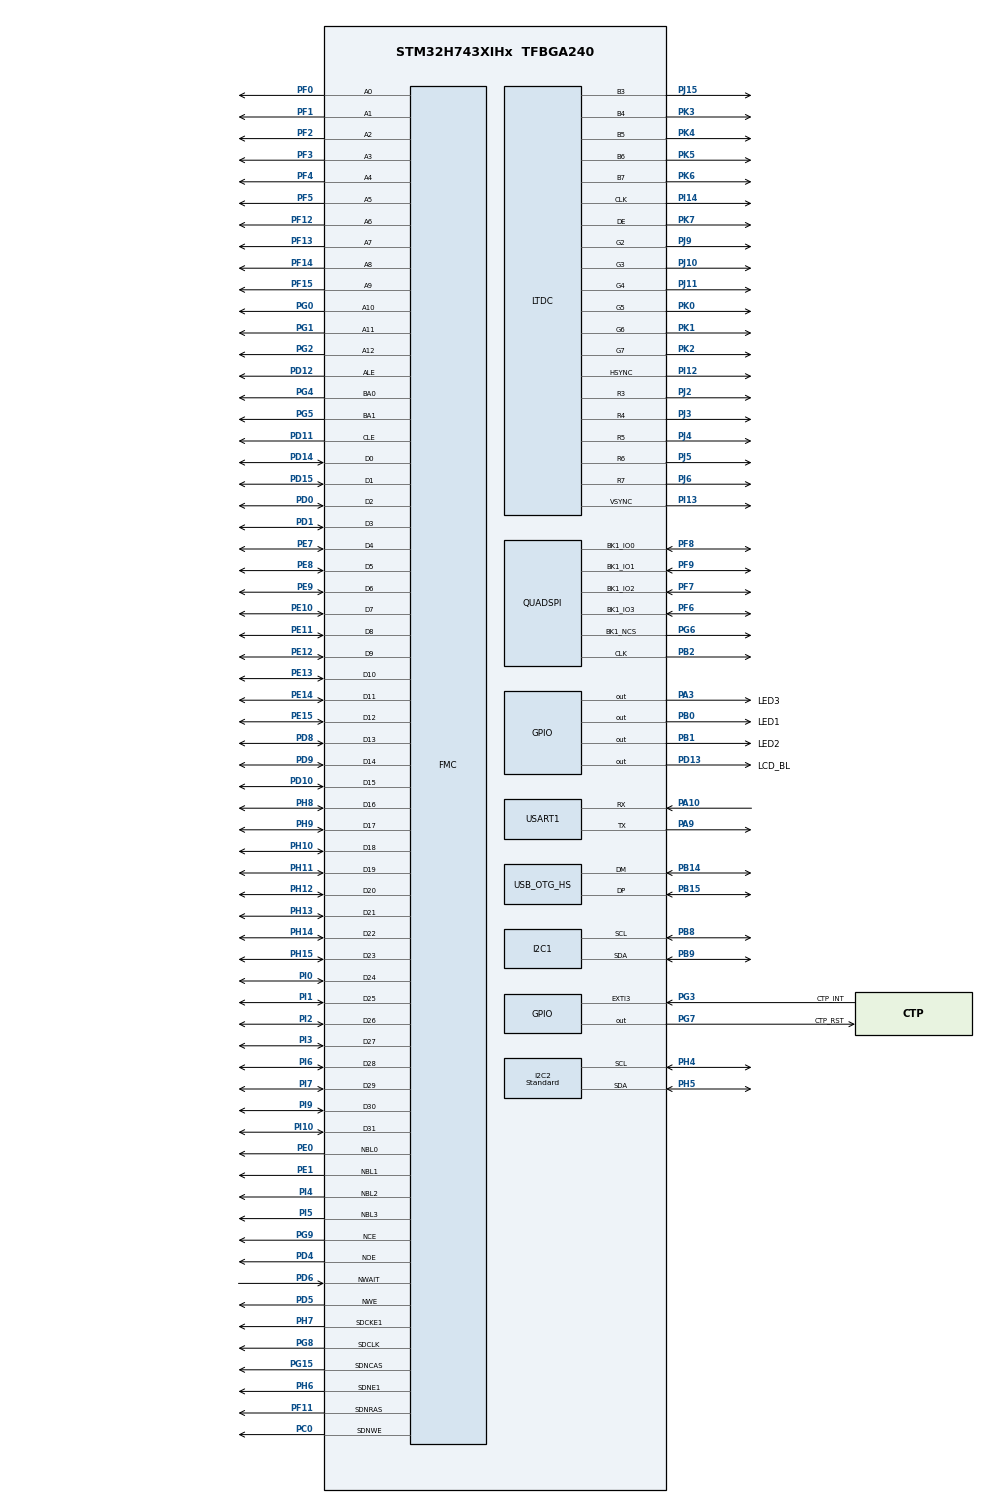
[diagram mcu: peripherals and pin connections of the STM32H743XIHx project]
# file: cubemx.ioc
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CORTEX_M7.default_mode_Activation=1
DMA2D.ColorMode=DMA2D_OUTPUT_RGB565
FATFS._USE_LABEL=1
FATFS._USE_LFN=3
FMC.CASLatency2=FMC_SDRAM_CAS_LATENCY_3
FMC.ColumnBitsNumber2=FMC_SDRAM_COLUMN_BITS_NUM_9
FMC.ExitSelfRefreshDelay2=8
FMC.LoadToActiveDelay2=2
FMC.RCDDelay2=2
FMC.RPDelay2=2
FMC.ReadBurst2=FMC_SDRAM_RBURST_ENABLE
FMC.ReadPipeDelay2=FMC_SDRAM_RPIPE_DELAY_1
FMC.RowCycleDelay2=8
FMC.SDClockPeriod2=FMC_SDRAM_CLOCK_PERIOD_2
FMC.SelfRefreshTime2=5
FMC.WriteRecoveryTime2=4
FREERTOS.Tasks01=defaultTask,24,128,StartDefaultTask,Default,NULL,Dynamic,NULL,NULL
FREERTOS.configENABLE_FPU=1
FREERTOS.configTOTAL_HEAP_SIZE=30720
I2C1.Timing=0x307075B1
I2C2.I2C_Speed_Mode=I2C_Standard
I2C2.Speed=100
I2C2.Timing=0x307075B1
LTDC.ActiveW=800
LTDC.Alpha_L0=255
LTDC.FBStartAdress_L0=0xD0000000
LTDC.HBP=46
LTDC.HFP=40
LTDC.HSync=1
LTDC.ImageHeight_L0=480
LTDC.ImageWidth_L0=800
LTDC.ImageWidth_L1=0
LTDC.PixelFormat_L0=LTDC_PIXEL_FORMAT_RGB565
LTDC.PixelFormat_L1=LTDC_PIXEL_FORMAT_ARGB8888
LTDC.VBP=23
LTDC.VFP=13
LTDC.VSync=3
LTDC.WindowX1_L0=800
LTDC.WindowY1_L0=480
Mcu.Family=STM32H7
Mcu.Name=STM32H743XIHx
Mcu.Package=TFBGA240
NVIC.DMA2D_IRQn=true\:5\:0\:false\:false\:true\:true\:true\:true\:true
NVIC.EXTI3_IRQn=true\:5\:0\:false\:false\:true\:true\:true\:true\:true
NVIC.OTG_HS_IRQn=true\:5\:0\:false\:false\:true\:true\:false\:true\:true
NVIC.PriorityGroup=NVIC_PRIORITYGROUP_4
NVIC.TIM6_DAC_IRQn=true\:15\:0\:false\:false\:true\:false\:false\:true\:true
NVIC.TimeBase=TIM6_DAC_IRQn
NVIC.TimeBaseIP=TIM6
PA10.Mode=Asynchronous
PA10.Signal=USART1_RX
PA13\ (JTMS/SWDIO).Mode=Serial_Wire
PA13\ (JTMS/SWDIO).Signal=DEBUG_JTMS-SWDIO
PA14\ (JTCK/SWCLK).Mode=Serial_Wire
PA14\ (JTCK/SWCLK).Signal=DEBUG_JTCK-SWCLK
PA3.GPIO_Label=LED3
PA3.GPIO_Speed=GPIO_SPEED_FREQ_HIGH
PA3.PinState=GPIO_PIN_SET
PA3.Signal=GPIO_Output
PA9.Mode=Asynchronous
PA9.Signal=USART1_TX
PB0.GPIO_Label=LED1
PB0.GPIO_Speed=GPIO_SPEED_FREQ_HIGH
PB0.PinState=GPIO_PIN_SET
PB0.Signal=GPIO_Output
PB1.GPIO_Label=LED2
PB1.GPIO_Speed=GPIO_SPEED_FREQ_HIGH
PB1.PinState=GPIO_PIN_SET
PB1.Signal=GPIO_Output
PB14.GPIO_Speed=GPIO_SPEED_FREQ_MEDIUM
PB14.Mode=Device_Only_FS
PB14.Signal=USB_OTG_HS_DM
PB15.GPIO_Speed=GPIO_SPEED_FREQ_MEDIUM
PB15.Mode=Device_Only_FS
PB15.Signal=USB_OTG_HS_DP
PB2.GPIO_Speed=GPIO_SPEED_FREQ_VERY_HIGH
PB2.Mode=Single Bank 1
PB2.Signal=QUADSPI_CLK
PB8.Mode=I2C
PB8.Signal=I2C1_SCL
PB9.Mode=I2C
PB9.Signal=I2C1_SDA
PC0.Signal=FMC_SDNWE
PC14-OSC32_IN\ (OSC32_IN).Mode=LSE-External-Oscillator
PC14-OSC32_IN\ (OSC32_IN).Signal=RCC_OSC32_IN
PC15-OSC32_OUT\ (OSC32_OUT).Mode=LSE-External-Oscillator
PC15-OSC32_OUT\ (OSC32_OUT).Signal=RCC_OSC32_OUT
PD0.Signal=FMC_D2_DA2
PD1.Signal=FMC_D3_DA3
PD10.Signal=FMC_D15_DA15
PD11.Signal=FMC_A16_CLE
PD12.Signal=FMC_A17_ALE
PD13.GPIO_Label=LCD_BL
PD13.GPIO_Speed=GPIO_SPEED_FREQ_HIGH
PD13.PinState=GPIO_PIN_RESET
PD13.Signal=GPIO_Output
PD14.Signal=FMC_D0_DA0
PD15.Signal=FMC_D1_DA1
PD4.Signal=FMC_NOE
PD5.Signal=FMC_NWE
PD6.Signal=FMC_NWAIT
PD8.Signal=FMC_D13_DA13
PD9.Signal=FMC_D14_DA14
PE0.Signal=FMC_NBL0
PE1.Signal=FMC_NBL1
PE10.Signal=FMC_D7_DA7
PE11.Signal=FMC_D8_DA8
PE12.Signal=FMC_D9_DA9
PE13.Signal=FMC_D10_DA10
PE14.Signal=FMC_D11_DA11
PE15.Signal=FMC_D12_DA12
PE7.Signal=FMC_D4_DA4
PE8.Signal=FMC_D5_DA5
PE9.Signal=FMC_D6_DA6
PF0.Signal=FMC_A0
PF1.Signal=FMC_A1
PF11.Signal=FMC_SDNRAS
PF12.Signal=FMC_A6
PF13.Signal=FMC_A7
PF14.Signal=FMC_A8
PF15.Signal=FMC_A9
PF2.Signal=FMC_A2
PF3.Signal=FMC_A3
PF4.Signal=FMC_A4
PF5.Signal=FMC_A5
PF6.GPIO_Speed=GPIO_SPEED_FREQ_VERY_HIGH
PF6.Mode=Single Bank 1
PF6.Signal=QUADSPI_BK1_IO3
PF7.GPIO_Speed=GPIO_SPEED_FREQ_VERY_HIGH
PF7.Mode=Single Bank 1
PF7.Signal=QUADSPI_BK1_IO2
PF8.GPIO_Speed=GPIO_SPEED_FREQ_VERY_HIGH
PF8.Mode=Single Bank 1
PF8.Signal=QUADSPI_BK1_IO0
PF9.GPIO_Speed=GPIO_SPEED_FREQ_VERY_HIGH
PF9.Mode=Single Bank 1
PF9.Signal=QUADSPI_BK1_IO1
PG0.Signal=FMC_A10
PG1.Signal=FMC_A11
PG15.Signal=FMC_SDNCAS
PG2.Signal=FMC_A12
PG3.GPIO_Label=CTP_INT
PG3.Signal=GPXTI3
PG4.Signal=FMC_A14_BA0
PG5.Signal=FMC_A15_BA1
PG6.GPIO_Speed=GPIO_SPEED_FREQ_VERY_HIGH
PG6.Mode=Single Bank 1
PG6.Signal=QUADSPI_BK1_NCS
PG7.GPIO_Label=CTP_RST
PG7.GPIO_Speed=GPIO_SPEED_FREQ_HIGH
PG7.Signal=GPIO_Output
PG8.Signal=FMC_SDCLK
PG9.Mode=NandChipSelect3_1
PG9.Signal=FMC_NCE
PH0-OSC_IN\ (PH0).Mode=HSE-External-Oscillator
PH0-OSC_IN\ (PH0).Signal=RCC_OSC_IN
PH1-OSC_OUT\ (PH1).Mode=HSE-External-Oscillator
PH1-OSC_OUT\ (PH1).Signal=RCC_OSC_OUT
PH10.Signal=FMC_D18
PH11.Signal=FMC_D19
PH12.Signal=FMC_D20
PH13.Signal=FMC_D21
PH14.Signal=FMC_D22
PH15.Signal=FMC_D23
PH4.GPIO_Speed=GPIO_SPEED_FREQ_VERY_HIGH
PH4.Mode=I2C
PH4.Signal=I2C2_SCL
PH5.GPIO_Speed=GPIO_SPEED_FREQ_VERY_HIGH
PH5.Mode=I2C
PH5.Signal=I2C2_SDA
PH6.Mode=SdramChipSelect2_2
PH6.Signal=FMC_SDNE1
PH7.Mode=SdramChipSelect2_2
PH7.Signal=FMC_SDCKE1
PH8.Signal=FMC_D16
PH9.Signal=FMC_D17
PI0.Signal=FMC_D24
PI1.Signal=FMC_D25
PI10.Signal=FMC_D31
PI12.GPIO_Speed=GPIO_SPEED_FREQ_HIGH
PI12.Mode=RGB565
PI12.Signal=LTDC_HSYNC
PI13.GPIO_Speed=GPIO_SPEED_FREQ_HIGH
PI13.Mode=RGB565
PI13.Signal=LTDC_VSYNC
PI14.GPIO_Speed=GPIO_SPEED_FREQ_HIGH
PI14.Mode=RGB565
PI14.Signal=LTDC_CLK
PI2.Signal=FMC_D26
PI3.Signal=FMC_D27
PI4.Signal=FMC_NBL2
PI5.Signal=FMC_NBL3
PI6.Signal=FMC_D28
PI7.Signal=FMC_D29
PI9.Signal=FMC_D30
PJ10.GPIO_Speed=GPIO_SPEED_FREQ_HIGH
PJ10.Mode=RGB565
PJ10.Signal=LTDC_G3
PJ11.GPIO_Speed=GPIO_SPEED_FREQ_HIGH
PJ11.Mode=RGB565
PJ11.Signal=LTDC_G4
PJ15.GPIO_Speed=GPIO_SPEED_FREQ_HIGH
PJ15.Mode=RGB565
PJ15.Signal=LTDC_B3
PJ2.GPIO_Speed=GPIO_SPEED_FREQ_HIGH
PJ2.Mode=RGB565
PJ2.Signal=LTDC_R3
PJ3.GPIO_Speed=GPIO_SPEED_FREQ_HIGH
PJ3.Mode=RGB565
PJ3.Signal=LTDC_R4
PJ4.GPIO_Speed=GPIO_SPEED_FREQ_HIGH
PJ4.Mode=RGB565
PJ4.Signal=LTDC_R5
PJ5.GPIO_Speed=GPIO_SPEED_FREQ_HIGH
PJ5.Mode=RGB565
PJ5.Signal=LTDC_R6
PJ6.GPIO_Speed=GPIO_SPEED_FREQ_HIGH
PJ6.Mode=RGB565
PJ6.Signal=LTDC_R7
PJ9.GPIO_Speed=GPIO_SPEED_FREQ_HIGH
PJ9.Mode=RGB565
PJ9.Signal=LTDC_G2
PK0.GPIO_Speed=GPIO_SPEED_FREQ_HIGH
PK0.Mode=RGB565
PK0.Signal=LTDC_G5
PK1.GPIO_Speed=GPIO_SPEED_FREQ_HIGH
PK1.Mode=RGB565
PK1.Signal=LTDC_G6
PK2.GPIO_Speed=GPIO_SPEED_FREQ_HIGH
PK2.Mode=RGB565
PK2.Signal=LTDC_G7
PK3.GPIO_Speed=GPIO_SPEED_FREQ_HIGH
PK3.Mode=RGB565
PK3.Signal=LTDC_B4
PK4.GPIO_Speed=GPIO_SPEED_FREQ_HIGH
PK4.Mode=RGB565
PK4.Signal=LTDC_B5
PK5.GPIO_Speed=GPIO_SPEED_FREQ_HIGH
PK5.Mode=RGB565
PK5.Signal=LTDC_B6
PK6.GPIO_Speed=GPIO_SPEED_FREQ_HIGH
PK6.Mode=RGB565
PK6.Signal=LTDC_B7
PK7.GPIO_Speed=GPIO_SPEED_FREQ_HIGH
PK7.Mode=RGB565
PK7.Signal=LTDC_DE
ProjectManager.HeapSize=0x200
ProjectManager.StackSize=0x1000
ProjectManager.TargetToolchain=MDK-ARM V5.32
QUADSPI.ChipSelectHighTime=QSPI_CS_HIGH_TIME_6_CYCLE
QUADSPI.ClockMode=QSPI_CLOCK_MODE_0
QUADSPI.ClockPrescaler=3
QUADSPI.FifoThreshold=4
QUADSPI.FlashSize=24
QUADSPI.SampleShifting=QSPI_SAMPLE_SHIFTING_HALFCYCLE
RCC.ADCFreq_Value=50390625
RCC.APB1Freq_Value=120000000
RCC.APB2Freq_Value=120000000
RCC.APB3Freq_Value=120000000
RCC.APB4Freq_Value=120000000
RCC.CortexFreq_Value=480000000
RCC.D1PPRE=RCC_APB3_DIV2
RCC.D2PPRE1=RCC_APB1_DIV2
RCC.D2PPRE2=RCC_APB2_DIV2
RCC.D3PPRE=RCC_APB4_DIV2
RCC.DIVM1=5
RCC.DIVM3=5
RCC.DIVN1=192
RCC.DIVN3=105
RCC.DIVQ3=11
RCC.DIVR3=16
RCC.HCLKFreq_Value=240000000
RCC.HPRE=RCC_HCLK_DIV2
RCC.PLL2FRACN=0
RCC.PLL3FRACN=4915
RCC.PLLFRACN=0
RCC.PLLSourceVirtual=RCC_PLLSOURCE_HSE
RCC.RTCClockSelection=RCC_RTCCLKSOURCE_LSE
RCC.SYSCLKFreq_VALUE=480000000
RCC.SYSCLKSource=RCC_SYSCLKSOURCE_PLLCLK
RCC.USBCLockSelection=RCC_USBCLKSOURCE_PLL3
RCC.USBFreq_Value=47999988.90269887
SH.FMC_A0.0=FMC_A0,13b-sda2
SH.FMC_A1.0=FMC_A1,13b-sda2
SH.FMC_A10.0=FMC_A10,13b-sda2
SH.FMC_A11.0=FMC_A11,13b-sda2
SH.FMC_A12.0=FMC_A12,13b-sda2
SH.FMC_A14_BA0.0=FMC_BA0,FourSdramBanks2
SH.FMC_A15_BA1.0=FMC_BA1,FourSdramBanks2
SH.FMC_A16_CLE.0=FMC_CLE,8b-dmux1
SH.FMC_A17_ALE.0=FMC_ALE,8b-dmux1
SH.FMC_A2.0=FMC_A2,13b-sda2
SH.FMC_A3.0=FMC_A3,13b-sda2
SH.FMC_A4.0=FMC_A4,13b-sda2
SH.FMC_A5.0=FMC_A5,13b-sda2
SH.FMC_A6.0=FMC_A6,13b-sda2
SH.FMC_A7.0=FMC_A7,13b-sda2
SH.FMC_A8.0=FMC_A8,13b-sda2
SH.FMC_A9.0=FMC_A9,13b-sda2
SH.FMC_D0_DA0.0=FMC_D0,sd-32b-d2
SH.FMC_D0_DA0.1=FMC_D0,8b-dmux1
SH.FMC_D10_DA10.0=FMC_D10,sd-32b-d2
SH.FMC_D11_DA11.0=FMC_D11,sd-32b-d2
SH.FMC_D12_DA12.0=FMC_D12,sd-32b-d2
SH.FMC_D13_DA13.0=FMC_D13,sd-32b-d2
SH.FMC_D14_DA14.0=FMC_D14,sd-32b-d2
SH.FMC_D15_DA15.0=FMC_D15,sd-32b-d2
SH.FMC_D16.0=FMC_D16,sd-32b-d2
SH.FMC_D17.0=FMC_D17,sd-32b-d2
SH.FMC_D18.0=FMC_D18,sd-32b-d2
SH.FMC_D19.0=FMC_D19,sd-32b-d2
SH.FMC_D1_DA1.0=FMC_D1,sd-32b-d2
SH.FMC_D1_DA1.1=FMC_D1,8b-dmux1
SH.FMC_D20.0=FMC_D20,sd-32b-d2
SH.FMC_D21.0=FMC_D21,sd-32b-d2
SH.FMC_D22.0=FMC_D22,sd-32b-d2
SH.FMC_D23.0=FMC_D23,sd-32b-d2
SH.FMC_D24.0=FMC_D24,sd-32b-d2
SH.FMC_D25.0=FMC_D25,sd-32b-d2
SH.FMC_D26.0=FMC_D26,sd-32b-d2
SH.FMC_D27.0=FMC_D27,sd-32b-d2
SH.FMC_D28.0=FMC_D28,sd-32b-d2
SH.FMC_D29.0=FMC_D29,sd-32b-d2
SH.FMC_D2_DA2.0=FMC_D2,sd-32b-d2
SH.FMC_D2_DA2.1=FMC_D2,8b-dmux1
SH.FMC_D30.0=FMC_D30,sd-32b-d2
SH.FMC_D31.0=FMC_D31,sd-32b-d2
SH.FMC_D3_DA3.0=FMC_D3,sd-32b-d2
SH.FMC_D3_DA3.1=FMC_D3,8b-dmux1
SH.FMC_D4_DA4.0=FMC_D4,sd-32b-d2
SH.FMC_D4_DA4.1=FMC_D4,8b-dmux1
SH.FMC_D5_DA5.0=FMC_D5,sd-32b-d2
SH.FMC_D5_DA5.1=FMC_D5,8b-dmux1
SH.FMC_D6_DA6.0=FMC_D6,sd-32b-d2
SH.FMC_D6_DA6.1=FMC_D6,8b-dmux1
SH.FMC_D7_DA7.0=FMC_D7,sd-32b-d2
SH.FMC_D7_DA7.1=FMC_D7,8b-dmux1
SH.FMC_D8_DA8.0=FMC_D8,sd-32b-d2
SH.FMC_D9_DA9.0=FMC_D9,sd-32b-d2
SH.FMC_NBL0.0=FMC_NBL0,Sd4ByteEnable2
SH.FMC_NBL1.0=FMC_NBL1,Sd4ByteEnable2
SH.FMC_NBL2.0=FMC_NBL2,Sd4ByteEnable2
SH.FMC_NBL3.0=FMC_NBL3,Sd4ByteEnable2
SH.FMC_NOE.0=FMC_NOE,8b-dmux1
SH.FMC_NWAIT.0=FMC_NWAIT,Wait1
SH.FMC_NWE.0=FMC_NWE,8b-dmux1
SH.FMC_SDCLK.0=FMC_SDCLK,13b-sda2
SH.FMC_SDNCAS.0=FMC_SDNCAS,13b-sda2
SH.FMC_SDNRAS.0=FMC_SDNRAS,13b-sda2
SH.FMC_SDNWE.0=FMC_SDNWE,13b-sda2
USART1.VirtualMode-Asynchronous=VM_ASYNC
USB_DEVICE.CLASS_NAME_HS=MSC
USB_DEVICE.MANUFACTURER_STRING-MSC_HS=ZLB
USB_DEVICE.PRODUCT_STRING_MSC_HS=STM32 QSPI Flash Disk
USB_DEVICE.VirtualMode-MSC_HS=Msc
USB_DEVICE.VirtualModeHS=Msc_HS
USB_OTG_HS.VirtualMode-Device_Only_FS=Device_Only_FS
VP_DMA2D_VS_DMA2D.Mode=DMA2D_Activate
VP_FATFS_VS_Generic.Mode=User_defined
VP_FREERTOS_VS_CMSIS_V2.Mode=CMSIS_V2
VP_MEMORYMAP_VS_MEMORYMAP.Mode=CurAppReg
VP_RTC_VS_RTC_Activate.Mode=RTC_Enabled
VP_SYS_VS_tim6.Mode=TIM6
VP_USB_DEVICE_VS_USB_DEVICE_MSC_HS.Mode=MSC_HS
board=custom

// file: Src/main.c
/* USER CODE BEGIN Header */
/**
  ******************************************************************************
  * @file           : main.c
  * @brief          : Main program body
  ******************************************************************************
  * @attention
  *
  * Copyright (c) 2026 STMicroelectronics.
  * All rights reserved.
  *
  * This software is licensed under terms that can be found in the LICENSE file
  * in the root directory of this software component.
  * If no LICENSE file comes with this software, it is provided AS-IS.
  *
  ******************************************************************************
  */
/* USER CODE END Header */
#include "main.h"
#include "FreeRTOS.h"
#include "cmsis_os2.h"
#include "dma2d.h"
#include "fatfs.h"
#include "i2c.h"
#include "ltdc.h"
#include "quadspi.h"
#include "rtc.h"
#include "usart.h"
#include "usb_device.h"
#include "gpio.h"
#include "fmc.h"

/* USER CODE BEGIN Includes */
#include "w25q256.h"
#include "stdio.h"
#include "string.h"
/* USER CODE END Includes */

void SystemClock_Config(void);
void PeriphCommonClock_Config(void);
static void MPU_Config(void);
void MX_FREERTOS_Init(void);

int main(void)
{

  /* MPU Configuration--------------------------------------------------------*/
  MPU_Config();

  /* MCU Configuration--------------------------------------------------------*/

  /* Reset of all peripherals, Initializes the Flash interface and the Systick. */
  HAL_Init();

  /* Configure the system clock */
  SystemClock_Config();

  /* Configure the peripherals common clocks */
  PeriphCommonClock_Config();

  /* Initialize all configured peripherals */
  MX_USART1_UART_Init();
  MX_GPIO_Init();
  MX_LTDC_Init();
  MX_RTC_Init();
  MX_DMA2D_Init();
  MX_I2C2_Init();
  MX_FMC_Init();
  MX_QUADSPI_Init();
  MX_I2C1_Init();
  //MX_FATFS_Init();

  /* Init scheduler */
  osKernelInitialize();  /* Call init function for freertos objects (in cmsis_os2.c) */
  MX_FREERTOS_Init();

  /* Start scheduler */
  osKernelStart();

  /* We should never get here as control is now taken by the scheduler */

  /* Infinite loop */
  while (1)
  {

  }
}

void SystemClock_Config(void)
{
  RCC_OscInitTypeDef RCC_OscInitStruct = {0};
  RCC_ClkInitTypeDef RCC_ClkInitStruct = {0};

  /** Supply configuration update enable
  */
  HAL_PWREx_ConfigSupply(PWR_LDO_SUPPLY);

  /** Configure the main internal regulator output voltage
  */
  __HAL_PWR_VOLTAGESCALING_CONFIG(PWR_REGULATOR_VOLTAGE_SCALE0);

  while(!__HAL_PWR_GET_FLAG(PWR_FLAG_VOSRDY)) {}

  /** Configure LSE Drive Capability
  */
  HAL_PWR_EnableBkUpAccess();
  __HAL_RCC_LSEDRIVE_CONFIG(RCC_LSEDRIVE_LOW);

  /** Initializes the RCC Oscillators according to the specified parameters
  * in the RCC_OscInitTypeDef structure.
  */
  RCC_OscInitStruct.OscillatorType = RCC_OSCILLATORTYPE_HSE|RCC_OSCILLATORTYPE_LSE;
  RCC_OscInitStruct.HSEState = RCC_HSE_ON;
  RCC_OscInitStruct.LSEState = RCC_LSE_ON;
  RCC_OscInitStruct.PLL.PLLState = RCC_PLL_ON;
  RCC_OscInitStruct.PLL.PLLSource = RCC_PLLSOURCE_HSE;
  RCC_OscInitStruct.PLL.PLLM = 5;
  RCC_OscInitStruct.PLL.PLLN = 192;
  RCC_OscInitStruct.PLL.PLLP = 2;
  RCC_OscInitStruct.PLL.PLLQ = 2;
  RCC_OscInitStruct.PLL.PLLR = 2;
  RCC_OscInitStruct.PLL.PLLRGE = RCC_PLL1VCIRANGE_2;
  RCC_OscInitStruct.PLL.PLLVCOSEL = RCC_PLL1VCOWIDE;
  RCC_OscInitStruct.PLL.PLLFRACN = 0;
  if (HAL_RCC_OscConfig(&RCC_OscInitStruct) != HAL_OK)
  {
    Error_Handler();
  }

  /** Initializes the CPU, AHB and APB buses clocks
  */
  RCC_ClkInitStruct.ClockType = RCC_CLOCKTYPE_HCLK|RCC_CLOCKTYPE_SYSCLK
                              |RCC_CLOCKTYPE_PCLK1|RCC_CLOCKTYPE_PCLK2
                              |RCC_CLOCKTYPE_D3PCLK1|RCC_CLOCKTYPE_D1PCLK1;
  RCC_ClkInitStruct.SYSCLKSource = RCC_SYSCLKSOURCE_PLLCLK;
  RCC_ClkInitStruct.SYSCLKDivider = RCC_SYSCLK_DIV1;
  RCC_ClkInitStruct.AHBCLKDivider = RCC_HCLK_DIV2;
  RCC_ClkInitStruct.APB3CLKDivider = RCC_APB3_DIV2;
  RCC_ClkInitStruct.APB1CLKDivider = RCC_APB1_DIV2;
  RCC_ClkInitStruct.APB2CLKDivider = RCC_APB2_DIV2;
  RCC_ClkInitStruct.APB4CLKDivider = RCC_APB4_DIV2;

  if (HAL_RCC_ClockConfig(&RCC_ClkInitStruct, FLASH_LATENCY_4) != HAL_OK)
  {
    Error_Handler();
  }
}

void PeriphCommonClock_Config(void)
{
  RCC_PeriphCLKInitTypeDef PeriphClkInitStruct = {0};

  /** Initializes the peripherals clock
  */
  PeriphClkInitStruct.PeriphClockSelection = RCC_PERIPHCLK_USB|RCC_PERIPHCLK_LTDC;
  PeriphClkInitStruct.PLL3.PLL3M = 5;
  PeriphClkInitStruct.PLL3.PLL3N = 105;
  PeriphClkInitStruct.PLL3.PLL3P = 2;
  PeriphClkInitStruct.PLL3.PLL3Q = 11;
  PeriphClkInitStruct.PLL3.PLL3R = 16;
  PeriphClkInitStruct.PLL3.PLL3RGE = RCC_PLL3VCIRANGE_2;
  PeriphClkInitStruct.PLL3.PLL3VCOSEL = RCC_PLL3VCOWIDE;
  PeriphClkInitStruct.PLL3.PLL3FRACN = 4915;
  PeriphClkInitStruct.UsbClockSelection = RCC_USBCLKSOURCE_PLL3;
  if (HAL_RCCEx_PeriphCLKConfig(&PeriphClkInitStruct) != HAL_OK)
  {
    Error_Handler();
  }
}

 /* MPU Configuration */

void MPU_Config(void)
{
  MPU_Region_InitTypeDef MPU_InitStruct = {0};

  /* Disables the MPU */
  HAL_MPU_Disable();

  /** Initializes and configures the Region and the memory to be protected
  */
  MPU_InitStruct.Enable = MPU_REGION_ENABLE;
  MPU_InitStruct.Number = MPU_REGION_NUMBER0;
  MPU_InitStruct.BaseAddress = 0x0;
  MPU_InitStruct.Size = MPU_REGION_SIZE_4GB;
  MPU_InitStruct.SubRegionDisable = 0x87;
  MPU_InitStruct.TypeExtField = MPU_TEX_LEVEL1;
  MPU_InitStruct.AccessPermission = MPU_REGION_NO_ACCESS;
  MPU_InitStruct.DisableExec = MPU_INSTRUCTION_ACCESS_DISABLE;
  MPU_InitStruct.IsShareable = MPU_ACCESS_NOT_SHAREABLE;
  MPU_InitStruct.IsCacheable = MPU_ACCESS_NOT_CACHEABLE;
  MPU_InitStruct.IsBufferable = MPU_ACCESS_NOT_BUFFERABLE;

  HAL_MPU_ConfigRegion(&MPU_InitStruct);

  /** Initializes and configures the Region and the memory to be protected
  * 外部 SDRAM: 64MB，给 framebuffer 和 LVGL heap 使用。
  * 先按非缓存区域打开，优先确保 LTDC/LVGL 访问稳定，不引入 cache 一致性问题。
  */
  MPU_InitStruct.Number = MPU_REGION_NUMBER1;
  MPU_InitStruct.BaseAddress = 0xD0000000;
  MPU_InitStruct.Size = MPU_REGION_SIZE_64MB;
  MPU_InitStruct.SubRegionDisable = 0x00;
  MPU_InitStruct.TypeExtField = MPU_TEX_LEVEL1;
  MPU_InitStruct.AccessPermission = MPU_REGION_FULL_ACCESS;
  MPU_InitStruct.DisableExec = MPU_INSTRUCTION_ACCESS_DISABLE;
  MPU_InitStruct.IsShareable = MPU_ACCESS_NOT_SHAREABLE;
  MPU_InitStruct.IsCacheable = MPU_ACCESS_NOT_CACHEABLE;
  MPU_InitStruct.IsBufferable = MPU_ACCESS_NOT_BUFFERABLE;
  HAL_MPU_ConfigRegion(&MPU_InitStruct);

  /* Enables the MPU */
  HAL_MPU_Enable(MPU_PRIVILEGED_DEFAULT);

}

void HAL_TIM_PeriodElapsedCallback(TIM_HandleTypeDef *htim)
{
  if (htim->Instance == TIM6)
  {
    HAL_IncTick();
  }
}

void Error_Handler(void)
{
  __disable_irq();
  while (1)
  {
  }
}

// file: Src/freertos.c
/* USER CODE BEGIN Header */
/**
  ******************************************************************************
  * File Name          : freertos.c
  * Description        : Code for freertos applications
  ******************************************************************************
  * @attention
  *
  * Copyright (c) 2026 STMicroelectronics.
  * All rights reserved.
  *
  * This software is licensed under terms that can be found in the LICENSE file
  * in the root directory of this software component.
  * If no LICENSE file comes with this software, it is provided AS-IS.
  *
  ******************************************************************************
  */
/* USER CODE END Header */

#include "FreeRTOS.h"
#include "task.h"
#include "main.h"
#include "FreeRTOS.h"
#include "cmsis_os2.h"

/* USER CODE BEGIN Includes */
#include <string.h>
#include "initial.h"
#include "lvgl.h"
#include "gui_test_app.h"
#include "custom.h"
#include "events_init.h"
/* USER CODE END Includes */

/* USER CODE BEGIN Variables */
osSemaphoreId_t LvglReadySemHandle;

/* USER CODE END Variables */
/* Definitions for defaultTask */
osThreadId_t defaultTaskHandle;
const osThreadAttr_t defaultTask_attributes = {
  .name = "defaultTask",
  .stack_size = 128 * 4,
  .priority = (osPriority_t) osPriorityNormal,
};

/* USER CODE BEGIN FunctionPrototypes */
osThreadId_t Initial_TaskHandle;
const osThreadAttr_t Initial_Task_attributes = {
  .name = "Initial_Task",
  .stack_size = 1024 * 4,
  .priority = (osPriority_t) osPriorityNormal,
};
osThreadId_t Display_TaskHandle;
const osThreadAttr_t Display_Task_attributes = {
  .name = "Display_Task",
  .stack_size = 4096 * 4,
  .priority = (osPriority_t) osPriorityNormal,
};
/* USER CODE END FunctionPrototypes */

void StartDefaultTask(void *argument);
void MX_FREERTOS_Init(void); /* (MISRA C 2004 rule 8.1) */
void Initial_Task(void *argument);
void Display_Task(void *argument);

void MX_FREERTOS_Init(void) {

  /* USER CODE BEGIN RTOS_SEMAPHORES */
  /* add semaphores, ... */
  LvglReadySemHandle = osSemaphoreNew(1, 0, NULL);
  /* USER CODE END RTOS_SEMAPHORES */

  /* Create the thread(s) */
  /* creation of defaultTask */
  defaultTaskHandle = osThreadNew(StartDefaultTask, NULL, &defaultTask_attributes);

  /* USER CODE BEGIN RTOS_THREADS */
  /* add threads, ... */
  Initial_TaskHandle = osThreadNew(Initial_Task, NULL, &Initial_Task_attributes);
  Display_TaskHandle = osThreadNew(Display_Task, NULL, &Display_Task_attributes);
  /* USER CODE END RTOS_THREADS */

}

void StartDefaultTask(void *argument)
{
  /* USER CODE BEGIN StartDefaultTask */

  /* Infinite loop */
  for(;;)
  {
    HAL_GPIO_TogglePin(LED1_GPIO_Port, LED1_Pin);
    osDelay(1000);
  }
  /* USER CODE END StartDefaultTask */
}

/* USER CODE BEGIN Application */
void Initial_Task(void *argument)
{
  initial();
  // initial() 完成前，Display_Task 不能碰任何 LVGL API，否则会在 setup_ui 里踩到未完成初始化的内存系统。
  osSemaphoreRelease(LvglReadySemHandle);
  Initial_TaskHandle = NULL;//严谨一点，把句柄删除了，防止误用
  osThreadExit();
}
void Display_Task(void *argument)
{
  osSemaphoreAcquire(LvglReadySemHandle, osWaitForever);// 等待 LVGL 初始化完成的信号。
  LvglReadySemHandle = NULL; // 严谨一点，把句柄删除了，防止误用。
  osSemaphoreDelete(LvglReadySemHandle);// 同样严谨一点，删除信号量，避免误用。

  // 只在 LVGL 初始化完成后创建界面对象，避免与 initial() 并发访问 LVGL 内部内存池。
  setup_ui(&guider_ui);
  events_init(&guider_ui);
  //custom_init(&guider_ui);
  for(;;)
  {
    // 这里放显示相关的周期性任务，比如 LVGL 的 lv_timer_handler 调度。
    lv_timer_handler();
    osDelay(10);  // LVGL 官方推荐 5~10ms 的调度周期。
  }
}
/* USER CODE END Application */
